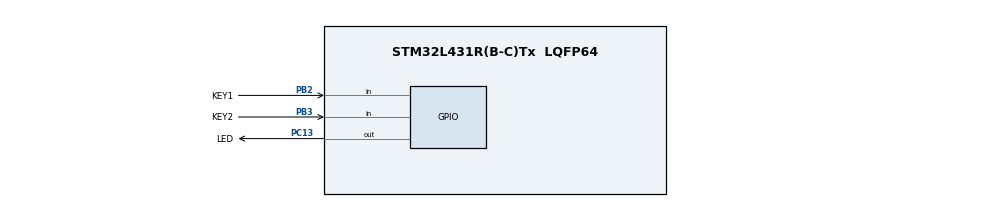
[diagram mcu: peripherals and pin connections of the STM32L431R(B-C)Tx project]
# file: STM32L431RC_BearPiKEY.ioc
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Mcu.Family=STM32L4
Mcu.Name=STM32L431R(B-C)Tx
Mcu.Package=LQFP64
NVIC.PriorityGroup=NVIC_PRIORITYGROUP_4
PB2.GPIO_Label=KEY1
PB2.GPIO_PuPd=GPIO_PULLUP
PB2.Signal=GPIO_Input
PB3\ (JTDO-TRACESWO).GPIO_Label=KEY2
PB3\ (JTDO-TRACESWO).GPIO_PuPd=GPIO_PULLUP
PB3\ (JTDO-TRACESWO).Signal=GPIO_Input
PC13.GPIO_Label=LED
PC13.Signal=GPIO_Output
ProjectManager.HeapSize=0x200
ProjectManager.StackSize=0x400
ProjectManager.TargetToolchain=MDK-ARM V5
RCC.HSE_VALUE=8000000
RCC.HSI48_VALUE=48000000
RCC.HSI_VALUE=16000000
RCC.LSE_VALUE=32768
RCC.MSI_VALUE=4000000
RCC.VCOOutputFreq_Value=32000000
board=custom

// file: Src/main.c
/* USER CODE BEGIN Header */
/**
  ******************************************************************************
  * @file           : main.c
  * @brief          : Main program body
  ******************************************************************************
  * @attention
  *
  * <h2><center>&copy; Copyright (c) 2020 STMicroelectronics.
  * All rights reserved.</center></h2>
  *
  * This software component is licensed by ST under BSD 3-Clause license,
  * the "License"; You may not use this file except in compliance with the
  * License. You may obtain a copy of the License at:
  *                        opensource.org/licenses/BSD-3-Clause
  *
  ******************************************************************************
  */
/* USER CODE END Header */

#include "main.h"
#include "gpio.h"

void SystemClock_Config(void);

int main(void)
{

  /* MCU Configuration--------------------------------------------------------*/

  /* Reset of all peripherals, Initializes the Flash interface and the Systick. */
  HAL_Init();

  /* Configure the system clock */
  SystemClock_Config();

  /* Initialize all configured peripherals */
  MX_GPIO_Init();

  /* Infinite loop */
  while (1)
  {

    /* USER CODE BEGIN 3 */
		if(HAL_GPIO_ReadPin(KEY1_GPIO_Port,KEY1_Pin) == GPIO_PIN_RESET){   // 查询 按键KEY1 低电平

			HAL_Delay(10);   //消抖

			if (HAL_GPIO_ReadPin(KEY1_GPIO_Port,KEY1_Pin) == GPIO_PIN_RESET){  //  查询 按键KEY1 低电平

				HAL_GPIO_WritePin(LED_GPIO_Port,LED_Pin,GPIO_PIN_SET); //亮

			}
		}

		if(HAL_GPIO_ReadPin(KEY2_GPIO_Port,KEY2_Pin) == GPIO_PIN_RESET){   // 查询 按键KEY2 低电平

			HAL_Delay(10);   //消抖

			if (HAL_GPIO_ReadPin(KEY2_GPIO_Port,KEY2_Pin) == GPIO_PIN_RESET){  //  查询 按键KEY2 低电平

				HAL_GPIO_WritePin(LED_GPIO_Port,LED_Pin,GPIO_PIN_RESET); //灭

			}
		}

  }
  /* USER CODE END 3 */
}

void SystemClock_Config(void)
{
  RCC_OscInitTypeDef RCC_OscInitStruct = {0};
  RCC_ClkInitTypeDef RCC_ClkInitStruct = {0};

  /** Initializes the CPU, AHB and APB busses clocks
  */
  RCC_OscInitStruct.OscillatorType = RCC_OSCILLATORTYPE_MSI;
  RCC_OscInitStruct.MSIState = RCC_MSI_ON;
  RCC_OscInitStruct.MSICalibrationValue = 0;
  RCC_OscInitStruct.MSIClockRange = RCC_MSIRANGE_6;
  RCC_OscInitStruct.PLL.PLLState = RCC_PLL_NONE;
  if (HAL_RCC_OscConfig(&RCC_OscInitStruct) != HAL_OK)
  {
    Error_Handler();
  }
  /** Initializes the CPU, AHB and APB busses clocks
  */
  RCC_ClkInitStruct.ClockType = RCC_CLOCKTYPE_HCLK|RCC_CLOCKTYPE_SYSCLK
                              |RCC_CLOCKTYPE_PCLK1|RCC_CLOCKTYPE_PCLK2;
  RCC_ClkInitStruct.SYSCLKSource = RCC_SYSCLKSOURCE_MSI;
  RCC_ClkInitStruct.AHBCLKDivider = RCC_SYSCLK_DIV1;
  RCC_ClkInitStruct.APB1CLKDivider = RCC_HCLK_DIV1;
  RCC_ClkInitStruct.APB2CLKDivider = RCC_HCLK_DIV1;

  if (HAL_RCC_ClockConfig(&RCC_ClkInitStruct, FLASH_LATENCY_0) != HAL_OK)
  {
    Error_Handler();
  }
  /** Configure the main internal regulator output voltage
  */
  if (HAL_PWREx_ControlVoltageScaling(PWR_REGULATOR_VOLTAGE_SCALE1) != HAL_OK)
  {
    Error_Handler();
  }
}

void Error_Handler(void)
{
}

/************************ (C) COPYRIGHT STMicroelectronics *****END OF FILE****/
